AUTOSAR XML (schema 4-0-3)
package /ComponentTypes
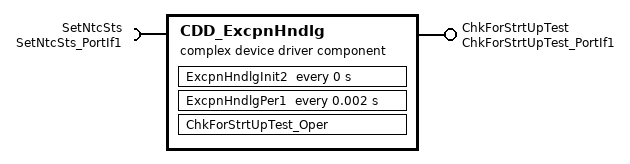
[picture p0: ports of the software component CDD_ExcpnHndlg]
  complex device driver sw component type CDD_ExcpnHndlg
    provide port ChkForStrtUpTest: server-com-spec{operation=Oper, queue-length=1}, provided-interface=ChkForStrtUpTest_PortIf1
    require port SetNtcSts: required-interface=SetNtcSts_PortIf1
    behavior CDD_ExcpnHndlg_InternalBehavior
      operation invoked event OIT_ChkForStrtUpTest_Oper_ChkForStrtUpTest_Oper: start-on-event=ChkForStrtUpTest_Oper, operation=ChkForStrtUpTest.Oper
      timing event CDD_ExcpnHndlg_InitEvent: start-on-event=ExcpnHndlgInit2, period=0
      timing event TMT_ExcpnHndlgPer1: start-on-event=ExcpnHndlgPer1, period=0.002
      runnable ChkForStrtUpTest_Oper
      runnable ExcpnHndlgInit2
        sync call SC_SetNtcSts_Oper: operation=SetNtcSts.Oper, timeout=0
      runnable ExcpnHndlgPer1
        sync call SC_SetNtcSts_Oper: operation=SetNtcSts.Oper, timeout=0
  swc implementation CDD_ExcpnHndlg_Implementation: behavior=CDD_ExcpnHndlg_InternalBehavior
    code-descriptors:
      code Default: artifact-descriptors=autosar-engineering-object={short-label=Default, category=SWSRC}
